# STM32H7P5 register map
File version: 2.0.0
CPU: CM7 r1p2, little endian, MPU, FPU, 4 interrupt priority bits
Registers are 32-bit, read-write, reset 0x0 unless marked. A register's access mark holds for its fields unless they carry their own. Offsets are from the block's base; [hi:lo] are bit positions; 'fields as' and 'values as' point back to an identical list.

## USART1 — USART register block
Base 0x42001000
Same registers: USART2 0x40004400, USART3 0x40004800, UART4 0x40004C00, UART5 0x40005000, UART7 0x40007800, UART8 0x40007C00, USART6 0x42001400, UART9 0x42001800, USART10 0x42001C00
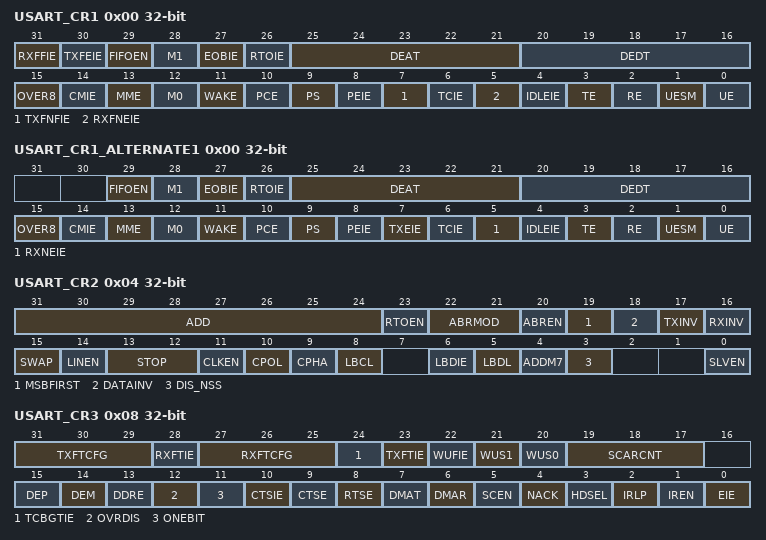
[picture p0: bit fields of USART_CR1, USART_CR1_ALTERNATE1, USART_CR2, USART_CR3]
0x00 USART_CR1 — USART control register 1
  [31] RXFFIE — RXFIFO Full interrupt enable
    0=Interrupt inhibited; 1=USART interrupt generated when RXFF=1 in the USART_ISR register
  [30] TXFEIE — TXFIFO empty interrupt enable
    0=Interrupt inhibited; 1=USART interrupt generated when TXFE=1 in the USART_ISR register
  [29] FIFOEN — FIFO mode enable
    0=FIFO mode is disabled; 1=FIFO mode is enabled
  [28] M1 — Word length
  [27] EOBIE — End of block interrupt enable
    0=Interrupt inhibited; 1=USART interrupt generated when the EOBF flag is set in the USART_ISR register
  [26] RTOIE — Receiver timeout interrupt enable
    0=Interrupt inhibited; 1=USART interrupt generated when the RTOF bit is set in the USART_ISR register
  [25:21] DEAT — Driver Enable assertion time
  [20:16] DEDT — Driver Enable deassertion time
  [15] OVER8 — Oversampling mode
    0=Oversampling by 16; 1=Oversampling by 8
  [14] CMIE — Character match interrupt enable
    0=Interrupt inhibited; 1=USART interrupt generated when the CMF bit is set in the USART_ISR register
  [13] MME — Mute mode enable
    0=Receiver in active mode permanently; 1=Receiver can switch between mute mode and active mode
  [12] M0 — Word length
  [11] WAKE — Receiver wake-up method
    0=Idle line; 1=Address mark
  [10] PCE — Parity control enable
    0=Parity control disabled; 1=Parity control enabled
  [9] PS — Parity selection
    0=Even parity; 1=Odd parity
  [8] PEIE — PE interrupt enable
    0=Interrupt inhibited; 1=USART interrupt generated whenever PE=1 in the USART_ISR register
  [7] TXFNFIE — TXFIFO not full interrupt enable
    0=Interrupt inhibited; 1=USART interrupt generated whenever TXFNF =1 in the USART_ISR register
  [6] TCIE — Transmission complete interrupt enable
    0=Interrupt inhibited; 1=USART interrupt generated whenever TC=1 in the USART_ISR register
  [5] RXFNEIE — RXFIFO not empty interrupt enable
    0=Interrupt inhibited; 1=USART interrupt generated whenever ORE=1 or RXFNE=1 in the USART_ISR register
  [4] IDLEIE — IDLE interrupt enable
    0=Interrupt inhibited; 1=USART interrupt generated whenever IDLE=1 in the USART_ISR register
  [3] TE — Transmitter enable
    0=Transmitter is disabled; 1=Transmitter is enabled
  [2] RE — Receiver enable
    0=Receiver is disabled; 1=Receiver is enabled and begins searching for a start bit
  [1] UESM — USART enable in low-power mode
    0=USART not able to wake up the MCU from low-power mode; 1=USART able to wake up the MCU from low-power mode
  [0] UE — USART enable
    0=USART prescaler and outputs disabled, low-power mode; 1=USART enabled
0x00 USART_CR1_ALTERNATE1 (alternate view of USART_CR1) — USART control register 1
  [29] FIFOEN — FIFO mode enable
    0=FIFO mode is disabled; 1=FIFO mode is enabled
  [28] M1 — Word length
  [27] EOBIE — End of block interrupt enable
    values as USART_CR1.EOBIE
  [26] RTOIE — Receiver timeout interrupt enable
    values as USART_CR1.RTOIE
  [25:21] DEAT — Driver Enable assertion time
  [20:16] DEDT — Driver Enable deassertion time
  [15] OVER8 — Oversampling mode
    0=Oversampling by 16; 1=Oversampling by 8
  [14] CMIE — Character match interrupt enable
    values as USART_CR1.CMIE
  [13] MME — Mute mode enable
    values as USART_CR1.MME
  [12] M0 — Word length
  [11] WAKE — Receiver wake-up method
    0=Idle line; 1=Address mark
  [10] PCE — Parity control enable
    0=Parity control disabled; 1=Parity control enabled
  [9] PS — Parity selection
    0=Even parity; 1=Odd parity
  [8] PEIE — PE interrupt enable
    values as USART_CR1.PEIE
  [7] TXEIE — Transmit data register empty
    0=Interrupt inhibited; 1=USART interrupt generated whenever TXE =1 in the USART_ISR register
  [6] TCIE — Transmission complete interrupt enable
    values as USART_CR1.TCIE
  [5] RXNEIE — Receive data register not empty
    0=Interrupt inhibited; 1=USART interrupt generated whenever ORE=1 or RXNE=1 in the USART_ISR register
  [4] IDLEIE — IDLE interrupt enable
    values as USART_CR1.IDLEIE
  [3] TE — Transmitter enable
    0=Transmitter is disabled; 1=Transmitter is enabled
  [2] RE — Receiver enable
    values as USART_CR1.RE
  [1] UESM — USART enable in low-power mode
    values as USART_CR1.UESM
  [0] UE — USART enable
    values as USART_CR1.UE
0x04 USART_CR2 — USART control register 2
  [31:24] ADD — Address of the USART node
  [23] RTOEN — Receiver timeout enable
    0=Receiver timeout feature disabled; 1=Receiver timeout feature enabled
  [22:21] ABRMOD — Auto baud rate mode
    0=Measurement of the start bit is used to detect the baud rate; 1=Falling edge to falling edge measurement (the received frame must start with a single bit = 1 -> Frame = Start10xxxxxx); 2=0x7F frame detection; 3=0x55 frame detection
  [20] ABREN — Auto baud rate enable
    0=Auto baud rate detection is disabled; 1=Auto baud rate detection is enabled
  [19] MSBFIRST — Most significant bit first
    0=data is transmitted/received with data bit 0 first, following the start bit; 1=data is transmitted/received with the MSB (bit 7/8) first, following the start bit
  [18] DATAINV — Binary data inversion
    0=Logical data from the data register are send/received in positive/direct logic. (1=H, 0=L); 1=Logical data from the data register are send/received in negative/inverse logic. (1=L, 0=H). The parity bit is also inverted.
  [17] TXINV — TX pin active level inversion
    0=TX pin signal works using the standard logic levels (Vless thansub>DDless than/sub>=1/idle, Gnd=0/mark); 1=TX pin signal values are inverted. ((Vless thansub>DDless than/sub>=0/mark, Gnd=1/idle).
  [16] RXINV — RX pin active level inversion
    0=RX pin signal works using the standard logic levels (Vless thansub>DDless than/sub>=1/idle, Gnd=0/mark); 1=RX pin signal values are inverted. ((Vless thansub>DDless than/sub>=0/mark, Gnd=1/idle).
  [15] SWAP — Swap TX/RX pins
    0=TX/RX pins are used as defined in standard pinout; 1=The TX and RX pins functions are swapped. This enables to work in the case of a cross-wired connection to another UART.
  [14] LINEN — LIN mode enable
    0=LIN mode disabled; 1=LIN mode enabled
  [13:12] STOP — Stop bits
    0=1 stop bit; 1=0.5 stop bit; 2=2 stop bits; 3=1.5 stop bits
  [11] CLKEN — Clock enable
    0=CK pin disabled; 1=CK pin enabled
  [10] CPOL — Clock polarity
    0=Steady low value on CK pin outside transmission window; 1=Steady high value on CK pin outside transmission window
  [9] CPHA — Clock phase
    0=The first clock transition is the first data capture edge; 1=The second clock transition is the first data capture edge
  [8] LBCL — Last bit clock pulse
    0=The clock pulse of the last data bit is not output to the CK pin; 1=The clock pulse of the last data bit is output to the CK pin
  [6] LBDIE — LIN break detection interrupt enable
    0=Interrupt is inhibited; 1=An interrupt is generated whenever LBDF=1 in the USART_ISR register
  [5] LBDL — LIN break detection length
    0=10-bit break detection; 1=11-bit break detection
  [4] ADDM7 — 7-bit address detection/4-bit address detection
    0=4-bit address detection; 1=7-bit address detection (in 8-bit data mode)
  [3] DIS_NSS — When the DIS_NSS bit is set, the NSS pin input is ignored.
    0=SPI slave selection depends on NSS input pin; 1=SPI slave is always selected and NSS input pin is ignored
  [0] SLVEN — Synchronous slave mode enable
    0=Slave mode disabled; 1=Slave mode enabled
0x08 USART_CR3 — USART control register 3
  [31:29] TXFTCFG — TXFIFO threshold configuration
    0=TXFIFO reaches 1/8 of its depth; 1=TXFIFO reaches 1/4 of its depth; 2=TXFIFO reaches 1/2 of its depth; 3=TXFIFO reaches 3/4 of its depth; 4=TXFIFO reaches 7/8 of its depth; 5=TXFIFO becomes empty
  [28] RXFTIE — RXFIFO threshold interrupt enable
    0=Interrupt inhibited; 1=USART interrupt generated when Receive FIFO reaches the threshold programmed in RXFTCFG[2:0]
  [27:25] RXFTCFG — Receive FIFO threshold configuration
    0=Receive FIFO reaches 1/8 of its depth; 1=Receive FIFO reaches 1/4 of its depth; 2=Receive FIFO reaches 1/2 of its depth; 3=Receive FIFO reaches 3/4 of its depth; 4=Receive FIFO reaches 7/8 of its depth; 5=Receive FIFO becomes full
  [24] TCBGTIE — Transmission Complete before guard time, interrupt enable
    0=Interrupt inhibited; 1=USART interrupt generated whenever TCBGT=1 in the USART_ISR register
  [23] TXFTIE — TXFIFO threshold interrupt enable
    0=Interrupt inhibited; 1=USART interrupt generated when TXFIFO reaches the threshold programmed in TXFTCFG[2:0]
  [22] WUFIE — Wake-up from low-power mode interrupt enable
    0=Interrupt inhibited; 1=USART interrupt generated whenever WUF=1 in the USART_ISR register
  [21] WUS1 — Wake-up from low-power mode interrupt flag selection
    0=WUF active on address match (as defined by ADD[7:0] and ADDM7)
  [20] WUS0 — Wake-up from low-power mode interrupt flag selection
    values as WUS1
  [19:17] SCARCNT — Smartcard auto-retry count
    0=retransmission disabled - No automatic retransmission in transmission mode
  [15] DEP — Driver enable polarity selection
    0=DE signal is active high; 1=DE signal is active low
  [14] DEM — Driver enable mode
    0=DE function is disabled; 1=DE function is enabled. The DE signal is output on the RTS pin.
  [13] DDRE — DMA Disable on reception Error
    0=DMA is not disabled in case of reception error. The corresponding error flag is set but RXNE is kept 0 preventing from overrun. As a consequence, the DMA request is not asserted, so the erroneous data is not transferred (no DMA request), but next correct received data is transferred. (used for smartcard mode); 1=DMA is disabled following a reception error. The corresponding error flag is set, as well as RXNE. The DMA request is masked until the error flag is cleared. This means that the software must first disable the DMA request (DMAR = 0) or clear RXNE(RXFNE is case FIFO mode is enabled) before clearing the error flag.
  [12] OVRDIS — Overrun Disable
    0=Overrun Error Flag, ORE, is set when received data is not read before receiving new data; 1=Overrun functionality is disabled. If new data is received while the RXNE flag is still set
  [11] ONEBIT — One sample bit method enable
    0=Three sample bit method; 1=One sample bit method
  [10] CTSIE — CTS interrupt enable
    0=Interrupt is inhibited; 1=An interrupt is generated whenever CTSIF=1 in the USART_ISR register
  [9] CTSE — CTS enable
    0=CTS hardware flow control disabled; 1=CTS mode enabled, data is only transmitted when the CTS input is deasserted (tied to 0). If the CTS input is asserted while data is being transmitted, then the transmission completes before stopping. If data is written into the data register while CTS is asserted, the transmission is postponed until CTS is deasserted.
  [8] RTSE — RTS enable
    0=RTS hardware flow control disabled; 1=RTS output enabled, data is only requested when there is space in the receive buffer. The transmission of data is expected to cease after the current character has been transmitted. The RTS output is deasserted (pulled to 0) when data can be received.
  [7] DMAT — DMA enable transmitter
    1=DMA mode is enabled for transmission; 0=DMA mode is disabled for transmission
  [6] DMAR — DMA enable receiver
    1=DMA mode is enabled for reception; 0=DMA mode is disabled for reception
  [5] SCEN — Smartcard mode enable
    0=Smartcard mode disabled; 1=Smartcard mode enabled
  [4] NACK — Smartcard NACK enable
    0=NACK transmission in case of parity error is disabled; 1=NACK transmission during parity error is enabled
  [3] HDSEL — Half-duplex selection
    0=Half-duplex mode is not selected; 1=Half-duplex mode is selected
  [2] IRLP — IrDA low-power
    0=Normal mode; 1=Low-power mode
  [1] IREN — IrDA mode enable
    0=IrDA disabled; 1=IrDA enabled
  [0] EIE — Error interrupt enable
    0=Interrupt inhibited; 1=interrupt generated when FE=1 or ORE=1 or NE=1 or UDR = 1 (in SPI slave mode) in the USART_ISR register
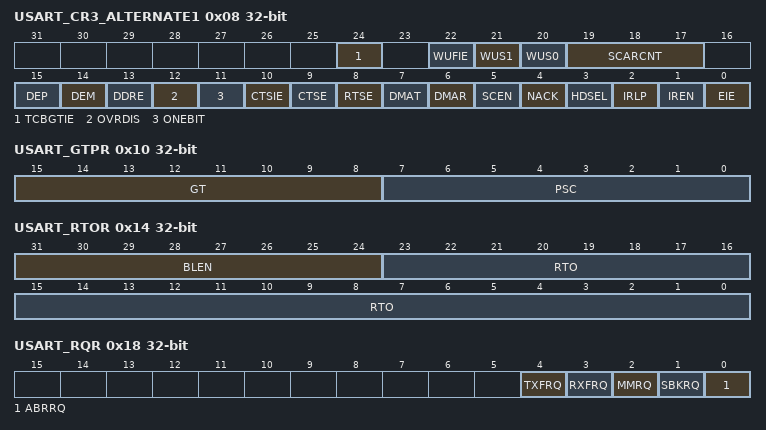
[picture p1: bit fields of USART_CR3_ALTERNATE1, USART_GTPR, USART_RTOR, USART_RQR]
0x08 USART_CR3_ALTERNATE1 (alternate view of USART_CR3) — USART control register 3
  [24] TCBGTIE — Transmission Complete before guard time, interrupt enable
    values as USART_CR3.TCBGTIE
  [22] WUFIE — Wake-up from low-power mode interrupt enable
    values as USART_CR3.WUFIE
  [21] WUS1 — Wake-up from low-power mode interrupt flag selection
    values as USART_CR3.WUS1
  [20] WUS0 — Wake-up from low-power mode interrupt flag selection
    values as USART_CR3.WUS1
  [19:17] SCARCNT — Smartcard auto-retry count
    values as USART_CR3.SCARCNT
  [15] DEP — Driver enable polarity selection
    0=DE signal is active high; 1=DE signal is active low
  [14] DEM — Driver enable mode
    values as USART_CR3.DEM
  [13] DDRE — DMA Disable on reception Error
    values as USART_CR3.DDRE
  [12] OVRDIS — Overrun Disable
    values as USART_CR3.OVRDIS
  [11] ONEBIT — One sample bit method enable
    0=Three sample bit method; 1=One sample bit method
  [10] CTSIE — CTS interrupt enable
    0=Interrupt is inhibited; 1=An interrupt is generated whenever CTSIF = 1 in the USART_ISR register
  [9] CTSE — CTS enable
    values as USART_CR3.CTSE
  [8] RTSE — RTS enable
    values as USART_CR3.RTSE
  [7] DMAT — DMA enable transmitter
    values as USART_CR3.DMAT
  [6] DMAR — DMA enable receiver
    values as USART_CR3.DMAR
  [5] SCEN — Smartcard mode enable
    0=Smartcard mode disabled; 1=Smartcard mode enabled
  [4] NACK — Smartcard NACK enable
    values as USART_CR3.NACK
  [3] HDSEL — Half-duplex selection
    values as USART_CR3.HDSEL
  [2] IRLP — IrDA low-power
    0=Normal mode; 1=Low-power mode
  [1] IREN — IrDA mode enable
    0=IrDA disabled; 1=IrDA enabled
  [0] EIE — Error interrupt enable
    values as USART_CR3.EIE
0x0C USART_BRR — USART baud rate register
  [15:0] BRR — USART baud rate
0x10 USART_GTPR — USART guard time and prescaler register
  [15:8] GT — Guard time value
  [7:0] PSC — Prescaler value
    1=B_0x1_IRDA_LOW_POWER_AND_NORMAL_IRDA_MODE (divides the source clock by 1); 2=B_0x2_IRDA_LOW_POWER_AND_NORMAL_IRDA_MODE (divides the source clock by 2); 3=B_0x3_SMARTCARD_MODE (divides the source clock by 6)
0x14 USART_RTOR — USART receiver timeout register
  [31:24] BLEN — Block Length
  [23:0] RTO — Receiver timeout value
0x18 USART_RQR wo — USART request register
  [4] TXFRQ — Transmit data flush request
  [3] RXFRQ — Receive data flush request
  [2] MMRQ — Mute mode request
  [1] SBKRQ — Send break request
  [0] ABRRQ — Auto baud rate request
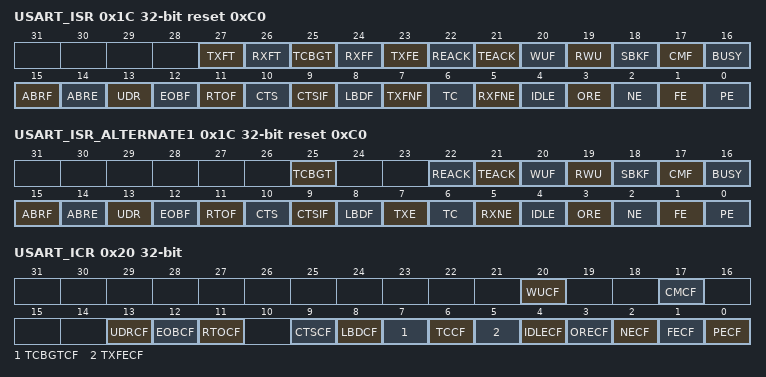
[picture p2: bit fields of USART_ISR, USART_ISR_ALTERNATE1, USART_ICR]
0x1C USART_ISR ro reset 0xC0 (reset mask 0xF00FFFFF) — USART interrupt and status register
  [27] TXFT — TXFIFO threshold flag
    0=TXFIFO does not reach the programmed threshold; 1=TXFIFO reached the programmed threshold
  [26] RXFT — RXFIFO threshold flag
    0=Receive FIFO does not reach the programmed threshold; 1=Receive FIFO reached the programmed threshold
  [25] TCBGT — Transmission complete before guard time flag
    0=Transmission has not completed, or transmission has completed unsuccessfully (that is, a NACK is received from the card); 1=Transmission has completed successfully (before Guard time completion and there is no NACK from the smart card)
  [24] RXFF — RXFIFO Full
    0=RXFIFO not full; 1=RXFIFO Full
  [23] TXFE — TXFIFO Empty
    0=TXFIFO not empty; 1=TXFIFO empty
  [22] REACK — Receive enable acknowledge flag
  [21] TEACK — Transmit enable acknowledge flag
  [20] WUF — Wake-up from low-power mode flag
  [19] RWU — Receiver wake-up from mute mode
    0=Receiver in active mode; 1=Receiver in mute mode
  [18] SBKF — Send break flag
    0=No break character transmitted; 1=Break character transmitted
  [17] CMF — Character match flag
    0=No Character match detected; 1=Character match detected
  [16] BUSY — Busy flag
    0=USART is idle (no reception); 1=Reception ongoing
  [15] ABRF — Auto baud rate flag
  [14] ABRE — Auto baud rate error
  [13] UDR — SPI slave underrun error flag
    0=No underrun error; 1=underrun error
  [12] EOBF — End of block flag
    0=End of block not reached; 1=End of block (number of characters) reached
  [11] RTOF — Receiver timeout
    0=Timeout value not reached; 1=Timeout value reached without any data reception
  [10] CTS — CTS flag
    0=CTS line set; 1=CTS line reset
  [9] CTSIF — CTS interrupt flag
    0=No change occurred on the CTS status line; 1=A change occurred on the CTS status line
  [8] LBDF — LIN break detection flag
    0=LIN Break not detected; 1=LIN break detected
  [7] TXFNF — TXFIFO not full
    0=Transmit FIFO is full; 1=Transmit FIFO is not full
  [6] TC — Transmission complete
    0=Transmission has not completed; 1=Transmission has completed
  [5] RXFNE — RXFIFO not empty
    0=Data is not received; 1=Received data is ready to be read
  [4] IDLE — Idle line detected
    0=No Idle line is detected; 1=Idle line is detected
  [3] ORE — Overrun error
    0=No overrun error; 1=Overrun error is detected
  [2] NE — Noise detection flag
    0=No noise is detected; 1=Noise is detected
  [1] FE — Framing error
    0=No Framing error is detected; 1=Framing error or break character is detected
  [0] PE — Parity error
    0=No parity error; 1=Parity error
0x1C USART_ISR_ALTERNATE1 ro reset 0xC0 (reset mask 0xF00FFFFF) (alternate view of USART_ISR) — USART interrupt and status register
  [25] TCBGT — Transmission complete before guard time flag
    0=Transmission has not completed or transmission has completed unsuccessfully (that is, a NACK is received from the card); 1=Transmission has not completed successfully (before Guard time completion and there is no NACK from the smart card)
  [22] REACK — Receive enable acknowledge flag
  [21] TEACK — Transmit enable acknowledge flag
  [20] WUF — Wake-up from low-power mode flag
  [19] RWU — Receiver wake-up from mute mode
    0=Receiver in active mode; 1=Receiver in mute mode
  [18] SBKF — Send break flag
    values as USART_ISR.SBKF
  [17] CMF — Character match flag
    0=No Character match detected; 1=Character match detected
  [16] BUSY — Busy flag
    0=USART is idle (no reception); 1=Reception ongoing
  [15] ABRF — Auto baud rate flag
  [14] ABRE — Auto baud rate error
  [13] UDR — SPI slave underrun error flag
    0=No underrun error; 1=underrun error
  [12] EOBF — End of block flag
    values as USART_ISR.EOBF
  [11] RTOF — Receiver timeout
    values as USART_ISR.RTOF
  [10] CTS — CTS flag
    0=CTS line set; 1=CTS line reset
  [9] CTSIF — CTS interrupt flag
    values as USART_ISR.CTSIF
  [8] LBDF — LIN break detection flag
    0=LIN Break not detected; 1=LIN break detected
  [7] TXE — Transmit data register empty
    0=Data register full; 1=Data register empty
  [6] TC — Transmission complete
  [5] RXNE — Read data register not empty
    0=Data is not received; 1=Received data is ready to be read
  [4] IDLE — Idle line detected
    0=No Idle line is detected; 1=Idle line is detected
  [3] ORE — Overrun error
    1=Overrun error is detected
  [2] NE — Noise detection flag
    0=No noise is detected; 1=Noise is detected
  [1] FE — Framing error
    values as USART_ISR.FE
  [0] PE — Parity error
    0=No parity error; 1=Parity error
0x20 USART_ICR wo — USART interrupt flag clear register
  [20] WUCF — Wake-up from low-power mode clear flag
  [17] CMCF — Character match clear flag
  [13] UDRCF — SPI slave underrun clear flag
  [12] EOBCF — End of block clear flag
  [11] RTOCF — Receiver timeout clear flag
  [9] CTSCF — CTS clear flag
  [8] LBDCF — LIN break detection clear flag
  [7] TCBGTCF — Transmission complete before Guard time clear flag
  [6] TCCF — Transmission complete clear flag
  [5] TXFECF — TXFIFO empty clear flag
  [4] IDLECF — Idle line detected clear flag
  [3] ORECF — Overrun error clear flag
  [2] NECF — Noise detected clear flag
  [1] FECF — Framing error clear flag
  [0] PECF — Parity error clear flag
0x24 USART_RDR ro — USART receive data register
  [8:0] RDR — Receive data value
0x28 USART_TDR — USART transmit data register
  [8:0] TDR — Transmit data value
0x2C USART_PRESC — USART prescaler register
  [3:0] PRESCALER — Clock prescaler
    0=input clock not divided; 1=input clock divided by 2; 2=input clock divided by 4; 3=input clock divided by 6; 4=input clock divided by 8; 5=input clock divided by 10; 6=input clock divided by 12; 7=input clock divided by 16; 8=input clock divided by 32; 9=input clock divided by 64; 10=input clock divided by 128; 11=input clock divided by 256
